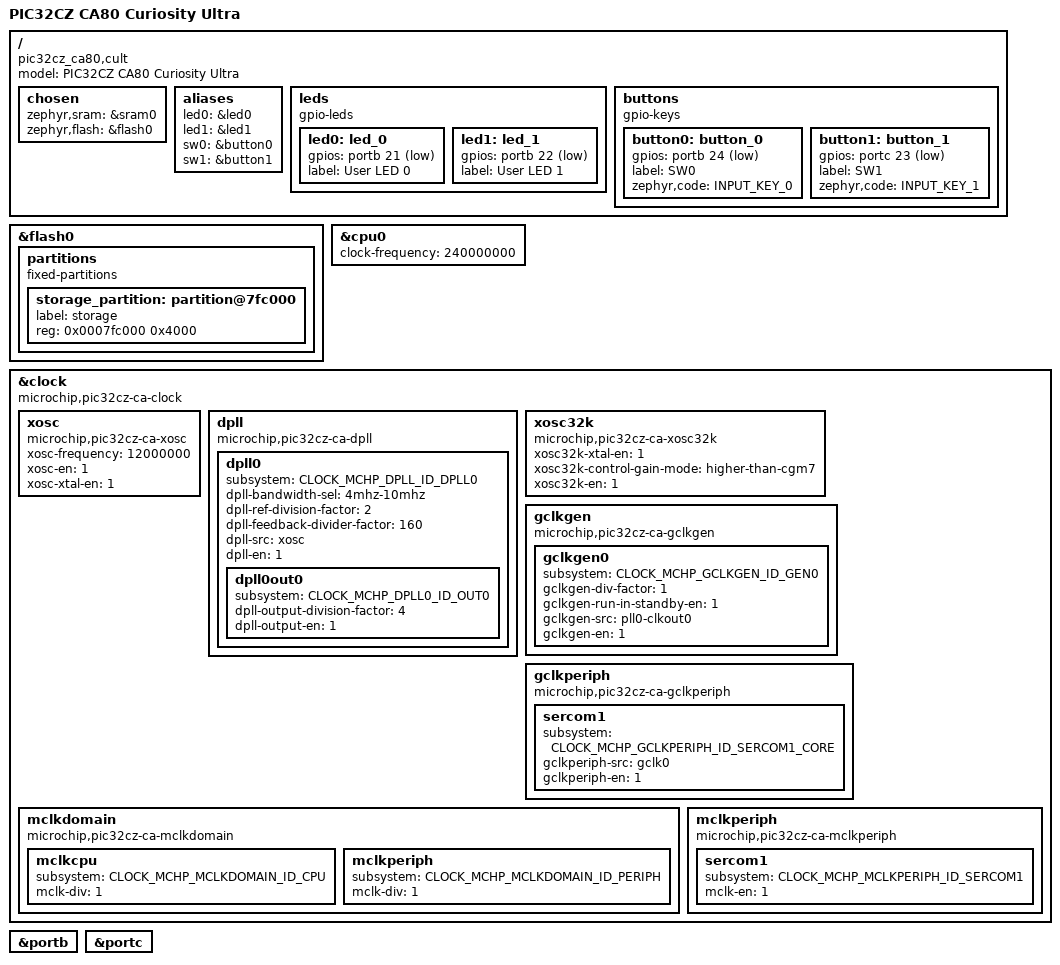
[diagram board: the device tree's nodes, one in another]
/*
 * Copyright (c) 2025-2026 Microchip Technology Inc.
 *
 * SPDX-License-Identifier: Apache-2.0
 */

/dts-v1/;
#include <microchip/pic32c/pic32cz_ca/pic32cz_ca80/pic32cz8110ca80208.dtsi>
#include <zephyr/dt-bindings/input/input-event-codes.h>

/ {
	model = "PIC32CZ CA80 Curiosity Ultra";
	compatible = "pic32cz_ca80,cult", "microchip,pic32cz8110ca80208", "microchip,pic32cz";

	chosen {
		zephyr,sram = &sram0;
		zephyr,flash = &flash0;
	};

	aliases {
		led0 = &led0;
		led1 = &led1;
		sw0 = &button0;
		sw1 = &button1;
	};

	leds {
		compatible = "gpio-leds";

		led0: led_0 {
			gpios = <&portb 21 GPIO_ACTIVE_LOW>;
			label = "User LED 0";
		};

		led1: led_1 {
			gpios = <&portb 22 GPIO_ACTIVE_LOW>;
			label = "User LED 1";
		};
	};

	buttons {
		compatible = "gpio-keys";

		button0: button_0 {
			gpios = <&portb 24 (GPIO_PULL_UP | GPIO_ACTIVE_LOW)>;
			label = "SW0";
			zephyr,code = <INPUT_KEY_0>;
		};

		button1: button_1 {
			gpios = <&portc 23 (GPIO_PULL_UP | GPIO_ACTIVE_LOW)>;
			label = "SW1";
			zephyr,code = <INPUT_KEY_1>;
		};
	};
};

&flash0 {
	partitions {
		compatible = "fixed-partitions";
		#address-cells = <1>;
		#size-cells = <1>;

		storage_partition: partition@7fc000 {
			label = "storage";
			reg = <0x0007fc000 0x4000>;
		};
	};
};

&cpu0 {
	clock-frequency = <240000000>;
};

&clock {
	compatible = "microchip,pic32cz-ca-clock";

	xosc: xosc {
		compatible = "microchip,pic32cz-ca-xosc";
		xosc-frequency = <12000000>;
		xosc-en = <1>;
		xosc-xtal-en = <1>;
	};

	dpll: dpll {
		compatible = "microchip,pic32cz-ca-dpll";

		dpll0: dpll0 {
			subsystem = <CLOCK_MCHP_DPLL_ID_DPLL0>;
			dpll-bandwidth-sel = "4mhz-10mhz";
			dpll-ref-division-factor = <2>;
			dpll-feedback-divider-factor = <160>;
			dpll-src = "xosc";
			dpll-en = <1>;

			dpll0out0: dpll0out0 {
				subsystem = <CLOCK_MCHP_DPLL0_ID_OUT0>;
				dpll-output-division-factor = <4>;
				dpll-output-en = <1>;
			};
		};
	};

	xosc32k: xosc32k {
		compatible = "microchip,pic32cz-ca-xosc32k";
		xosc32k-xtal-en = <1>;
		xosc32k-control-gain-mode = "higher-than-cgm7";
		xosc32k-en = <1>;
	};

	gclkgen: gclkgen {
		compatible = "microchip,pic32cz-ca-gclkgen";

		gclkgen0 {
			subsystem = <CLOCK_MCHP_GCLKGEN_ID_GEN0>;
			gclkgen-div-factor = <1>;
			gclkgen-run-in-standby-en = <1>;
			gclkgen-src = "pll0-clkout0";
			gclkgen-en = <1>;
		};
	};

	gclkperiph: gclkperiph {
		compatible = "microchip,pic32cz-ca-gclkperiph";
		#clock-cells = <1>;

		sercom1 {
			subsystem = <CLOCK_MCHP_GCLKPERIPH_ID_SERCOM1_CORE>;
			gclkperiph-src = "gclk0";
			gclkperiph-en = <1>;
		};
	};

	mclkdomain: mclkdomain {
		compatible = "microchip,pic32cz-ca-mclkdomain";

		mclkcpu {
			subsystem = <CLOCK_MCHP_MCLKDOMAIN_ID_CPU>;
			mclk-div = <1>;
		};

		mclkperiph {
			subsystem = <CLOCK_MCHP_MCLKDOMAIN_ID_PERIPH>;
			mclk-div = <1>;
		};
	};

	mclkperiph: mclkperiph {
		compatible = "microchip,pic32cz-ca-mclkperiph";
		#clock-cells = <1>;

		sercom1 {
			subsystem = <CLOCK_MCHP_MCLKPERIPH_ID_SERCOM1>;
			mclk-en = <1>;
		};
	};
};

&portb {
	status = "okay";
};

&portc {
	status = "okay";
};
